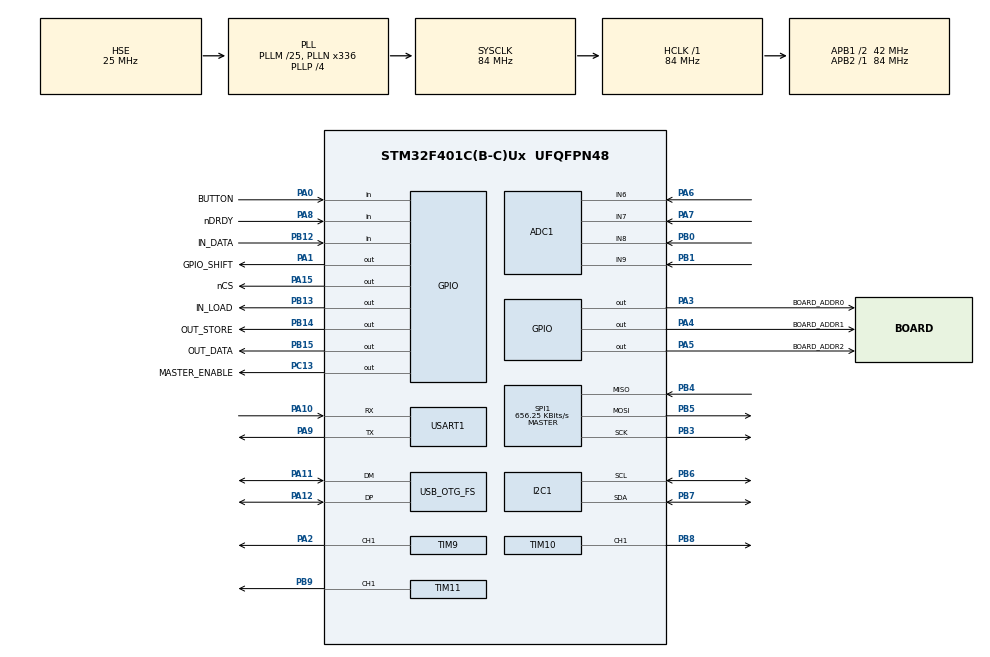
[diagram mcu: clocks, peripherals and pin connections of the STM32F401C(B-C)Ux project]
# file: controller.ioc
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ADC1.Channel-0\#ChannelRegularConversion=ADC_CHANNEL_VREFINT
ADC1.Channel-1\#ChannelRegularConversion=ADC_CHANNEL_6
ADC1.Channel-2\#ChannelRegularConversion=ADC_CHANNEL_7
ADC1.Channel-3\#ChannelRegularConversion=ADC_CHANNEL_VREFINT
ADC1.Channel-4\#ChannelRegularConversion=ADC_CHANNEL_8
ADC1.Channel-5\#ChannelRegularConversion=ADC_CHANNEL_9
ADC1.Channel-6\#ChannelRegularConversion=ADC_CHANNEL_TEMPSENSOR
ADC1.Channel-8\#ChannelRegularConversion=ADC_CHANNEL_VREFINT
ADC1.ClockPrescaler=ADC_CLOCK_SYNC_PCLK_DIV8
ADC1.ContinuousConvMode=DISABLE
ADC1.DMAContinuousRequests=ENABLE
ADC1.EOCSelection=ADC_EOC_SEQ_CONV
ADC1.ExternalTrigConv=ADC_EXTERNALTRIGCONV_T3_TRGO
ADC1.InjNumberOfConversion=0
ADC1.NbrOfConversion=8
ADC1.NbrOfConversionFlag=1
ADC1.Rank-0\#ChannelRegularConversion=1
ADC1.Rank-1\#ChannelRegularConversion=2
ADC1.Rank-2\#ChannelRegularConversion=3
ADC1.Rank-3\#ChannelRegularConversion=4
ADC1.Rank-4\#ChannelRegularConversion=5
ADC1.Rank-5\#ChannelRegularConversion=6
ADC1.Rank-6\#ChannelRegularConversion=7
ADC1.Rank-8\#ChannelRegularConversion=8
ADC1.SamplingTime-0\#ChannelRegularConversion=ADC_SAMPLETIME_480CYCLES
ADC1.SamplingTime-1\#ChannelRegularConversion=ADC_SAMPLETIME_480CYCLES
ADC1.SamplingTime-2\#ChannelRegularConversion=ADC_SAMPLETIME_480CYCLES
ADC1.SamplingTime-3\#ChannelRegularConversion=ADC_SAMPLETIME_480CYCLES
ADC1.SamplingTime-4\#ChannelRegularConversion=ADC_SAMPLETIME_480CYCLES
ADC1.SamplingTime-5\#ChannelRegularConversion=ADC_SAMPLETIME_480CYCLES
ADC1.SamplingTime-6\#ChannelRegularConversion=ADC_SAMPLETIME_480CYCLES
ADC1.SamplingTime-8\#ChannelRegularConversion=ADC_SAMPLETIME_480CYCLES
ADC1.ScanConvMode=ENABLE
ADC1.master=1
Dma.ADC1.0.Direction=DMA_PERIPH_TO_MEMORY
Dma.ADC1.0.FIFOMode=DMA_FIFOMODE_ENABLE
Dma.ADC1.0.FIFOThreshold=DMA_FIFO_THRESHOLD_FULL
Dma.ADC1.0.Instance=DMA2_Stream4
Dma.ADC1.0.MemBurst=DMA_MBURST_INC8
Dma.ADC1.0.MemDataAlignment=DMA_MDATAALIGN_HALFWORD
Dma.ADC1.0.MemInc=DMA_MINC_ENABLE
Dma.ADC1.0.Mode=DMA_CIRCULAR
Dma.ADC1.0.PeriphBurst=DMA_PBURST_SINGLE
Dma.ADC1.0.PeriphDataAlignment=DMA_PDATAALIGN_HALFWORD
Dma.ADC1.0.PeriphInc=DMA_PINC_DISABLE
Dma.ADC1.0.Priority=DMA_PRIORITY_MEDIUM
Dma.Request0=ADC1
I2C1.I2C_Mode=I2C_Fast
Mcu.Family=STM32F4
Mcu.Name=STM32F401C(B-C)Ux
Mcu.Package=UFQFPN48
Mcu.UserConstants=MOTOR_TIMER_MIN_VALUE,200-1;MOTOR_TIMER_PULSE_WIDTH,MOTOR_TIMER_MIN_VALUE/2
NVIC.DMA2_Stream4_IRQn=true\:2\:0\:true\:false\:true\:false\:true\:true
NVIC.OTG_FS_IRQn=true\:0\:0\:false\:false\:true\:false\:true\:true
NVIC.PriorityGroup=NVIC_PRIORITYGROUP_4
NVIC.RTC_Alarm_IRQn=true\:4\:0\:true\:false\:true\:true\:true\:true
NVIC.TIM1_UP_TIM10_IRQn=true\:2\:0\:true\:false\:true\:true\:true\:true
NVIC.TIM3_IRQn=true\:3\:0\:true\:false\:true\:true\:true\:true
NVIC.TIM4_IRQn=true\:0\:0\:false\:false\:true\:true\:true\:true
NVIC.USART1_IRQn=true\:0\:0\:false\:false\:true\:true\:true\:true
PA0-WKUP.GPIO_Label=BUTTON
PA0-WKUP.GPIO_PuPd=GPIO_PULLUP
PA0-WKUP.Signal=GPIO_Input
PA1.GPIO_Label=GPIO_SHIFT
PA1.Signal=GPIO_Output
PA10.GPIO_Speed=GPIO_SPEED_FREQ_MEDIUM
PA10.Mode=Asynchronous
PA10.Signal=USART1_RX
PA11.GPIO_Speed=GPIO_SPEED_FREQ_HIGH
PA11.Mode=Device_Only
PA11.Signal=USB_OTG_FS_DM
PA12.GPIO_Speed=GPIO_SPEED_FREQ_HIGH
PA12.Mode=Device_Only
PA12.Signal=USB_OTG_FS_DP
PA13.Mode=Serial_Wire
PA13.Signal=SYS_JTMS-SWDIO
PA14.Mode=Serial_Wire
PA14.Signal=SYS_JTCK-SWCLK
PA15.GPIO_Label=nCS
PA15.Signal=GPIO_Output
PA2.Signal=S_TIM9_CH1
PA3.GPIO_Label=BOARD_ADDR0
PA3.Signal=GPIO_Output
PA4.GPIO_Label=BOARD_ADDR1
PA4.Signal=GPIO_Output
PA5.GPIO_Label=BOARD_ADDR2
PA5.Signal=GPIO_Output
PA6.Signal=ADCx_IN6
PA7.Signal=ADCx_IN7
PA8.GPIO_Label=nDRDY
PA8.GPIO_PuPd=GPIO_PULLUP
PA8.Signal=GPIO_Input
PA9.GPIO_Speed=GPIO_SPEED_FREQ_MEDIUM
PA9.Mode=Asynchronous
PA9.Signal=USART1_TX
PB0.Signal=ADCx_IN8
PB1.Signal=ADCx_IN9
PB12.GPIO_Label=IN_DATA
PB12.Signal=GPIO_Input
PB13.GPIO_Label=IN_LOAD
PB13.Signal=GPIO_Output
PB14.GPIO_Label=OUT_STORE
PB14.Signal=GPIO_Output
PB15.GPIO_Label=OUT_DATA
PB15.Signal=GPIO_Output
PB3.GPIO_Speed=GPIO_SPEED_FREQ_MEDIUM
PB3.Mode=Full_Duplex_Master
PB3.Signal=SPI1_SCK
PB4.GPIO_Speed=GPIO_SPEED_FREQ_MEDIUM
PB4.Mode=Full_Duplex_Master
PB4.Signal=SPI1_MISO
PB5.GPIO_Speed=GPIO_SPEED_FREQ_MEDIUM
PB5.Mode=Full_Duplex_Master
PB5.Signal=SPI1_MOSI
PB6.GPIO_Pu=GPIO_PULLUP
PB6.GPIO_Speed=GPIO_SPEED_FREQ_MEDIUM
PB6.Mode=I2C
PB6.Signal=I2C1_SCL
PB7.GPIO_Pu=GPIO_PULLUP
PB7.GPIO_Speed=GPIO_SPEED_FREQ_MEDIUM
PB7.Mode=I2C
PB7.Signal=I2C1_SDA
PB8.Signal=S_TIM10_CH1
PB9.Signal=S_TIM11_CH1
PC13-ANTI_TAMP.GPIO_Label=MASTER_ENABLE
PC13-ANTI_TAMP.Signal=GPIO_Output
PC14-OSC32_IN.Mode=LSE-External-Oscillator
PC14-OSC32_IN.Signal=RCC_OSC32_IN
PC15-OSC32_OUT.Mode=LSE-External-Oscillator
PC15-OSC32_OUT.Signal=RCC_OSC32_OUT
PH0\ -\ OSC_IN.Mode=HSE-External-Oscillator
PH0\ -\ OSC_IN.Signal=RCC_OSC_IN
PH1\ -\ OSC_OUT.Mode=HSE-External-Oscillator
PH1\ -\ OSC_OUT.Signal=RCC_OSC_OUT
ProjectManager.HeapSize=0x200
ProjectManager.StackSize=0x400
ProjectManager.TargetToolchain=Makefile
RCC.48MHZClocksFreq_Value=48000000
RCC.AHBFreq_Value=84000000
RCC.APB1CLKDivider=RCC_HCLK_DIV2
RCC.APB1Freq_Value=42000000
RCC.APB1TimFreq_Value=84000000
RCC.APB2Freq_Value=84000000
RCC.APB2TimFreq_Value=84000000
RCC.CortexFreq_Value=84000000
RCC.EnbaleCSS=true
RCC.HCLKFreq_Value=84000000
RCC.HSE_VALUE=25000000
RCC.HSICalibrationValue=16
RCC.HSI_VALUE=16000000
RCC.LSE_Timout=500
RCC.PLLM=25
RCC.PLLN=336
RCC.PLLP=RCC_PLLP_DIV4
RCC.PLLQ=7
RCC.PWR_Regulator_Voltage_Scale=PWR_REGULATOR_VOLTAGE_SCALE2
RCC.RCC_RTC_Clock_SourceVirtual=RCC_RTCCLKSOURCE_LSE
RCC.SYSCLKFreq_VALUE=84000000
RCC.SYSCLKSource=RCC_SYSCLKSOURCE_PLLCLK
RCC.VCOOutputFreq_Value=336000000
RTC.Alarm=RTC_ALARM_A
RTC.AlarmMaskDateWeekDay=RTC_ALARMMASK_DATEWEEKDAY
RTC.AlarmMaskHours=RTC_ALARMMASK_HOURS
RTC.AlarmMaskMinutes=RTC_ALARMMASK_MINUTES
RTC.AlarmMaskSeconds=RTC_ALARMMASK_SECONDS
RTC.AlarmSubSecondMask=RTC_ALARMSUBSECONDMASK_ALL
RTC.AsynchPrediv=127
RTC.Format=RTC_FORMAT_BCD
RTC.SubSeconds_A=0
RTC.SynchPrediv=255
RTC.Year=21
SH.ADCx_IN6.0=ADC1_IN6,IN6
SH.ADCx_IN7.0=ADC1_IN7,IN7
SH.ADCx_IN8.0=ADC1_IN8,IN8
SH.ADCx_IN9.0=ADC1_IN9,IN9
SH.S_TIM10_CH1.0=TIM10_CH1,PWM Generation1 CH1
SH.S_TIM11_CH1.0=TIM11_CH1,PWM Generation1 CH1
SH.S_TIM9_CH1.0=TIM9_CH1,PWM Generation1 CH1
SPI1.BaudRatePrescaler=SPI_BAUDRATEPRESCALER_128
SPI1.CLKPhase=SPI_PHASE_2EDGE
SPI1.CRCCalculation=SPI_CRCCALCULATION_DISABLE
SPI1.CalculateBaudRate=656.25 KBits/s
SPI1.Direction=SPI_DIRECTION_2LINES
SPI1.Mode=SPI_MODE_MASTER
SPI1.VirtualType=VM_MASTER
TIM10.AutoReloadPreload=TIM_AUTORELOAD_PRELOAD_ENABLE
TIM10.Channel=TIM_CHANNEL_1
TIM10.Prescaler=130-1
TIM10.Pulse=MOTOR_TIMER_PULSE_WIDTH
TIM11.AutoReloadPreload=TIM_AUTORELOAD_PRELOAD_ENABLE
TIM11.Channel=TIM_CHANNEL_1
TIM11.Prescaler=130-1
TIM11.Pulse=MOTOR_TIMER_PULSE_WIDTH
TIM3.Period=60000-1
TIM3.Prescaler=140-1
TIM3.TIM_MasterOutputTrigger=TIM_TRGO_UPDATE
TIM3.TIM_MasterSlaveMode=TIM_MASTERSLAVEMODE_ENABLE
TIM4.Period=30000
TIM4.Prescaler=140-1
TIM4.TIM_MasterOutputTrigger=TIM_TRGO_UPDATE
TIM4.TIM_MasterSlaveMode=TIM_MASTERSLAVEMODE_ENABLE
TIM5.Period=4294967295
TIM5.Prescaler=84-1
TIM9.AutoReloadPreload=TIM_AUTORELOAD_PRELOAD_ENABLE
TIM9.Channel-PWM\ Generation1\ CH1=TIM_CHANNEL_1
TIM9.Prescaler=130-1
TIM9.Pulse-PWM\ Generation1\ CH1=MOTOR_TIMER_PULSE_WIDTH
USART1.Parity=PARITY_ODD
USART1.VirtualMode=VM_ASYNC
USB_DEVICE.APP_RX_DATA_SIZE=512
USB_DEVICE.APP_TX_DATA_SIZE=512
USB_DEVICE.CLASS_NAME_FS=CDC
USB_DEVICE.MANUFACTURER_STRING=Kutukov Pavel
USB_DEVICE.PID_CDC_FS=0x5740
USB_DEVICE.PRODUCT_STRING_CDC_FS=pO2 regulator - STM32 Serial
USB_DEVICE.USBD_MAX_STR_DESC_SIZ=128
USB_DEVICE.USBD_SELF_POWERED=0
USB_DEVICE.VID=0x483
USB_DEVICE.VirtualMode=Cdc
USB_DEVICE.VirtualModeFS=Cdc_FS
USB_OTG_FS.VirtualMode=Device_Only
VP_ADC1_TempSens_Input.Mode=IN-TempSens
VP_ADC1_Vref_Input.Mode=IN-Vrefint
VP_RTC_VS_RTC_Activate.Mode=RTC_Enabled
VP_RTC_VS_RTC_Alarm_A_Intern.Mode=Alarm A
VP_RTC_VS_RTC_Calendar.Mode=RTC_Calendar
VP_TIM10_VS_ClockSourceINT.Mode=Enable_Timer
VP_TIM11_VS_ClockSourceINT.Mode=Enable_Timer
VP_TIM3_VS_ClockSourceINT.Mode=Internal
VP_TIM4_VS_ClockSourceINT.Mode=Internal
VP_TIM4_VS_ClockSourceITR.Mode=TriggerSource_ITR2
VP_TIM4_VS_ControllerModeTrigger.Mode=Trigger Mode
VP_TIM4_VS_OPM.Mode=OPM_bit
VP_TIM5_VS_ClockSourceINT.Mode=Internal
VP_TIM9_VS_ClockSourceINT.Mode=Internal
VP_USB_DEVICE_VS_USB_DEVICE_CDC_FS.Mode=CDC_FS
board=custom

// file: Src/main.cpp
/* USER CODE BEGIN Header */
/**
  ******************************************************************************
  * @file           : main.c
  * @brief          : Main program body
  ******************************************************************************
  * @attention
  *
  * Copyright (c) 2023 STMicroelectronics.
  * All rights reserved.
  *
  * This software is licensed under terms that can be found in the LICENSE file
  * in the root directory of this software component.
  * If no LICENSE file comes with this software, it is provided AS-IS.
  *
  ******************************************************************************
  */
/* USER CODE END Header */
#include "main.h"
#include "usb_device.h"

/* USER CODE BEGIN Includes */
#include "user.h"
/* USER CODE END Includes */

ADC_HandleTypeDef hadc1;
DMA_HandleTypeDef hdma_adc1;

I2C_HandleTypeDef hi2c1;

RTC_HandleTypeDef hrtc;

SPI_HandleTypeDef hspi1;

TIM_HandleTypeDef htim3;
TIM_HandleTypeDef htim4;
TIM_HandleTypeDef htim5;
TIM_HandleTypeDef htim9;
TIM_HandleTypeDef htim10;
TIM_HandleTypeDef htim11;

UART_HandleTypeDef huart1;

void SystemClock_Config(void);
static void MX_GPIO_Init(void);
static void MX_DMA_Init(void);
static void MX_ADC1_Init(void);
static void MX_I2C1_Init(void);
static void MX_SPI1_Init(void);
static void MX_TIM3_Init(void);
static void MX_TIM9_Init(void);
static void MX_TIM10_Init(void);
static void MX_TIM11_Init(void);
static void MX_RTC_Init(void);
static void MX_USART1_UART_Init(void);
static void MX_TIM5_Init(void);
static void MX_TIM4_Init(void);

int main(void)
{

  /* MCU Configuration--------------------------------------------------------*/

  /* Reset of all peripherals, Initializes the Flash interface and the Systick. */
  HAL_Init();

  /* Configure the system clock */
  SystemClock_Config();

  /* Initialize all configured peripherals */
  MX_GPIO_Init();
  MX_DMA_Init();
  MX_ADC1_Init();
  MX_I2C1_Init();
  MX_SPI1_Init();
  MX_TIM3_Init();
  MX_TIM9_Init();
  MX_TIM10_Init();
  MX_TIM11_Init();
  MX_RTC_Init();
  MX_USART1_UART_Init();
  MX_USB_DEVICE_Init();
  MX_TIM5_Init();
  MX_TIM4_Init();
  /* USER CODE BEGIN 2 */
  user::setup(&hspi1, &hspi1, &hi2c1, &hadc1, &huart1);
  /* USER CODE END 2 */

  /* Infinite loop */
  while (1)
  {
    user::main();
  }
}

void SystemClock_Config(void)
{
  RCC_OscInitTypeDef RCC_OscInitStruct = {0};
  RCC_ClkInitTypeDef RCC_ClkInitStruct = {0};

  /** Configure the main internal regulator output voltage
  */
  __HAL_RCC_PWR_CLK_ENABLE();
  __HAL_PWR_VOLTAGESCALING_CONFIG(PWR_REGULATOR_VOLTAGE_SCALE2);

  /** Initializes the RCC Oscillators according to the specified parameters
  * in the RCC_OscInitTypeDef structure.
  */
  RCC_OscInitStruct.OscillatorType = RCC_OSCILLATORTYPE_HSE|RCC_OSCILLATORTYPE_LSE;
  RCC_OscInitStruct.HSEState = RCC_HSE_ON;
  RCC_OscInitStruct.LSEState = RCC_LSE_ON;
  RCC_OscInitStruct.PLL.PLLState = RCC_PLL_ON;
  RCC_OscInitStruct.PLL.PLLSource = RCC_PLLSOURCE_HSE;
  RCC_OscInitStruct.PLL.PLLM = 25;
  RCC_OscInitStruct.PLL.PLLN = 336;
  RCC_OscInitStruct.PLL.PLLP = RCC_PLLP_DIV4;
  RCC_OscInitStruct.PLL.PLLQ = 7;
  if (HAL_RCC_OscConfig(&RCC_OscInitStruct) != HAL_OK)
  {
    Error_Handler();
  }

  /** Initializes the CPU, AHB and APB buses clocks
  */
  RCC_ClkInitStruct.ClockType = RCC_CLOCKTYPE_HCLK|RCC_CLOCKTYPE_SYSCLK
                              |RCC_CLOCKTYPE_PCLK1|RCC_CLOCKTYPE_PCLK2;
  RCC_ClkInitStruct.SYSCLKSource = RCC_SYSCLKSOURCE_PLLCLK;
  RCC_ClkInitStruct.AHBCLKDivider = RCC_SYSCLK_DIV1;
  RCC_ClkInitStruct.APB1CLKDivider = RCC_HCLK_DIV2;
  RCC_ClkInitStruct.APB2CLKDivider = RCC_HCLK_DIV1;

  if (HAL_RCC_ClockConfig(&RCC_ClkInitStruct, FLASH_LATENCY_2) != HAL_OK)
  {
    Error_Handler();
  }

  /** Enables the Clock Security System
  */
  HAL_RCC_EnableCSS();
}

static void MX_ADC1_Init(void)
{

  ADC_ChannelConfTypeDef sConfig = {0};

  /** Configure the global features of the ADC (Clock, Resolution, Data Alignment and number of conversion)
  */
  hadc1.Instance = ADC1;
  hadc1.Init.ClockPrescaler = ADC_CLOCK_SYNC_PCLK_DIV8;
  hadc1.Init.Resolution = ADC_RESOLUTION_12B;
  hadc1.Init.ScanConvMode = ENABLE;
  hadc1.Init.ContinuousConvMode = DISABLE;
  hadc1.Init.DiscontinuousConvMode = DISABLE;
  hadc1.Init.ExternalTrigConvEdge = ADC_EXTERNALTRIGCONVEDGE_RISING;
  hadc1.Init.ExternalTrigConv = ADC_EXTERNALTRIGCONV_T3_TRGO;
  hadc1.Init.DataAlign = ADC_DATAALIGN_RIGHT;
  hadc1.Init.NbrOfConversion = 8;
  hadc1.Init.DMAContinuousRequests = ENABLE;
  hadc1.Init.EOCSelection = ADC_EOC_SEQ_CONV;
  if (HAL_ADC_Init(&hadc1) != HAL_OK)
  {
    Error_Handler();
  }

  /** Configure for the selected ADC regular channel its corresponding rank in the sequencer and its sample time.
  */
  sConfig.Channel = ADC_CHANNEL_VREFINT;
  sConfig.Rank = 1;
  sConfig.SamplingTime = ADC_SAMPLETIME_480CYCLES;
  if (HAL_ADC_ConfigChannel(&hadc1, &sConfig) != HAL_OK)
  {
    Error_Handler();
  }

  /** Configure for the selected ADC regular channel its corresponding rank in the sequencer and its sample time.
  */
  sConfig.Channel = ADC_CHANNEL_6;
  sConfig.Rank = 2;
  if (HAL_ADC_ConfigChannel(&hadc1, &sConfig) != HAL_OK)
  {
    Error_Handler();
  }

  /** Configure for the selected ADC regular channel its corresponding rank in the sequencer and its sample time.
  */
  sConfig.Channel = ADC_CHANNEL_7;
  sConfig.Rank = 3;
  if (HAL_ADC_ConfigChannel(&hadc1, &sConfig) != HAL_OK)
  {
    Error_Handler();
  }

  /** Configure for the selected ADC regular channel its corresponding rank in the sequencer and its sample time.
  */
  sConfig.Channel = ADC_CHANNEL_VREFINT;
  sConfig.Rank = 4;
  if (HAL_ADC_ConfigChannel(&hadc1, &sConfig) != HAL_OK)
  {
    Error_Handler();
  }

  /** Configure for the selected ADC regular channel its corresponding rank in the sequencer and its sample time.
  */
  sConfig.Channel = ADC_CHANNEL_8;
  sConfig.Rank = 5;
  if (HAL_ADC_ConfigChannel(&hadc1, &sConfig) != HAL_OK)
  {
    Error_Handler();
  }

  /** Configure for the selected ADC regular channel its corresponding rank in the sequencer and its sample time.
  */
  sConfig.Channel = ADC_CHANNEL_9;
  sConfig.Rank = 6;
  if (HAL_ADC_ConfigChannel(&hadc1, &sConfig) != HAL_OK)
  {
    Error_Handler();
  }

  /** Configure for the selected ADC regular channel its corresponding rank in the sequencer and its sample time.
  */
  sConfig.Channel = ADC_CHANNEL_TEMPSENSOR;
  sConfig.Rank = 7;
  if (HAL_ADC_ConfigChannel(&hadc1, &sConfig) != HAL_OK)
  {
    Error_Handler();
  }

  /** Configure for the selected ADC regular channel its corresponding rank in the sequencer and its sample time.
  */
  sConfig.Channel = ADC_CHANNEL_VREFINT;
  sConfig.Rank = 8;
  if (HAL_ADC_ConfigChannel(&hadc1, &sConfig) != HAL_OK)
  {
    Error_Handler();
  }

}

static void MX_I2C1_Init(void)
{

  hi2c1.Instance = I2C1;
  hi2c1.Init.ClockSpeed = 400000;
  hi2c1.Init.DutyCycle = I2C_DUTYCYCLE_2;
  hi2c1.Init.OwnAddress1 = 0;
  hi2c1.Init.AddressingMode = I2C_ADDRESSINGMODE_7BIT;
  hi2c1.Init.DualAddressMode = I2C_DUALADDRESS_DISABLE;
  hi2c1.Init.OwnAddress2 = 0;
  hi2c1.Init.GeneralCallMode = I2C_GENERALCALL_DISABLE;
  hi2c1.Init.NoStretchMode = I2C_NOSTRETCH_DISABLE;
  if (HAL_I2C_Init(&hi2c1) != HAL_OK)
  {
    Error_Handler();
  }

}

static void MX_RTC_Init(void)
{

  RTC_TimeTypeDef sTime = {0};
  RTC_DateTypeDef sDate = {0};
  RTC_AlarmTypeDef sAlarm = {0};

  /** Initialize RTC Only
  */
  hrtc.Instance = RTC;
  hrtc.Init.HourFormat = RTC_HOURFORMAT_24;
  hrtc.Init.AsynchPrediv = 127;
  hrtc.Init.SynchPrediv = 255;
  hrtc.Init.OutPut = RTC_OUTPUT_DISABLE;
  hrtc.Init.OutPutPolarity = RTC_OUTPUT_POLARITY_HIGH;
  hrtc.Init.OutPutType = RTC_OUTPUT_TYPE_OPENDRAIN;
  if (HAL_RTC_Init(&hrtc) != HAL_OK)
  {
    Error_Handler();
  }

  /** Initialize RTC and set the Time and Date
  */
  sTime.Hours = 0x0;
  sTime.Minutes = 0x0;
  sTime.Seconds = 0x0;
  sTime.DayLightSaving = RTC_DAYLIGHTSAVING_NONE;
  sTime.StoreOperation = RTC_STOREOPERATION_RESET;
  if (HAL_RTC_SetTime(&hrtc, &sTime, RTC_FORMAT_BCD) != HAL_OK)
  {
    Error_Handler();
  }
  sDate.WeekDay = RTC_WEEKDAY_MONDAY;
  sDate.Month = RTC_MONTH_JANUARY;
  sDate.Date = 0x1;
  sDate.Year = 0x21;

  if (HAL_RTC_SetDate(&hrtc, &sDate, RTC_FORMAT_BCD) != HAL_OK)
  {
    Error_Handler();
  }

  /** Enable the Alarm A
  */
  sAlarm.AlarmTime.Hours = 0x0;
  sAlarm.AlarmTime.Minutes = 0x0;
  sAlarm.AlarmTime.Seconds = 0x0;
  sAlarm.AlarmTime.SubSeconds = 0x0;
  sAlarm.AlarmTime.DayLightSaving = RTC_DAYLIGHTSAVING_NONE;
  sAlarm.AlarmTime.StoreOperation = RTC_STOREOPERATION_RESET;
  sAlarm.AlarmMask = RTC_ALARMMASK_ALL;
  sAlarm.AlarmSubSecondMask = RTC_ALARMSUBSECONDMASK_ALL;
  sAlarm.AlarmDateWeekDaySel = RTC_ALARMDATEWEEKDAYSEL_DATE;
  sAlarm.AlarmDateWeekDay = 0x1;
  sAlarm.Alarm = RTC_ALARM_A;
  if (HAL_RTC_SetAlarm_IT(&hrtc, &sAlarm, RTC_FORMAT_BCD) != HAL_OK)
  {
    Error_Handler();
  }

}

static void MX_SPI1_Init(void)
{

  /* SPI1 parameter configuration*/
  hspi1.Instance = SPI1;
  hspi1.Init.Mode = SPI_MODE_MASTER;
  hspi1.Init.Direction = SPI_DIRECTION_2LINES;
  hspi1.Init.DataSize = SPI_DATASIZE_8BIT;
  hspi1.Init.CLKPolarity = SPI_POLARITY_LOW;
  hspi1.Init.CLKPhase = SPI_PHASE_2EDGE;
  hspi1.Init.NSS = SPI_NSS_SOFT;
  hspi1.Init.BaudRatePrescaler = SPI_BAUDRATEPRESCALER_128;
  hspi1.Init.FirstBit = SPI_FIRSTBIT_MSB;
  hspi1.Init.TIMode = SPI_TIMODE_DISABLE;
  hspi1.Init.CRCCalculation = SPI_CRCCALCULATION_DISABLE;
  hspi1.Init.CRCPolynomial = 10;
  if (HAL_SPI_Init(&hspi1) != HAL_OK)
  {
    Error_Handler();
  }

}

static void MX_TIM3_Init(void)
{

  TIM_ClockConfigTypeDef sClockSourceConfig = {0};
  TIM_MasterConfigTypeDef sMasterConfig = {0};

  htim3.Instance = TIM3;
  htim3.Init.Prescaler = 140-1;
  htim3.Init.CounterMode = TIM_COUNTERMODE_UP;
  htim3.Init.Period = 60000-1;
  htim3.Init.ClockDivision = TIM_CLOCKDIVISION_DIV1;
  htim3.Init.AutoReloadPreload = TIM_AUTORELOAD_PRELOAD_DISABLE;
  if (HAL_TIM_Base_Init(&htim3) != HAL_OK)
  {
    Error_Handler();
  }
  sClockSourceConfig.ClockSource = TIM_CLOCKSOURCE_INTERNAL;
  if (HAL_TIM_ConfigClockSource(&htim3, &sClockSourceConfig) != HAL_OK)
  {
    Error_Handler();
  }
  sMasterConfig.MasterOutputTrigger = TIM_TRGO_UPDATE;
  sMasterConfig.MasterSlaveMode = TIM_MASTERSLAVEMODE_ENABLE;
  if (HAL_TIMEx_MasterConfigSynchronization(&htim3, &sMasterConfig) != HAL_OK)
  {
    Error_Handler();
  }
  /* USER CODE BEGIN TIM3_Init 2 */
  HAL_TIM_Base_Start_IT(&htim3);
  /* USER CODE END TIM3_Init 2 */

}

static void MX_TIM4_Init(void)
{

  TIM_ClockConfigTypeDef sClockSourceConfig = {0};
  TIM_SlaveConfigTypeDef sSlaveConfig = {0};
  TIM_MasterConfigTypeDef sMasterConfig = {0};

  htim4.Instance = TIM4;
  htim4.Init.Prescaler = 140-1;
  htim4.Init.CounterMode = TIM_COUNTERMODE_UP;
  htim4.Init.Period = 10000;
  htim4.Init.ClockDivision = TIM_CLOCKDIVISION_DIV1;
  htim4.Init.AutoReloadPreload = TIM_AUTORELOAD_PRELOAD_DISABLE;
  if (HAL_TIM_Base_Init(&htim4) != HAL_OK)
  {
    Error_Handler();
  }
  sClockSourceConfig.ClockSource = TIM_CLOCKSOURCE_INTERNAL;
  if (HAL_TIM_ConfigClockSource(&htim4, &sClockSourceConfig) != HAL_OK)
  {
    Error_Handler();
  }
  if (HAL_TIM_OnePulse_Init(&htim4, TIM_OPMODE_SINGLE) != HAL_OK)
  {
    Error_Handler();
  }
  sSlaveConfig.SlaveMode = TIM_SLAVEMODE_TRIGGER;
  sSlaveConfig.InputTrigger = TIM_TS_ITR2;
  if (HAL_TIM_SlaveConfigSynchro(&htim4, &sSlaveConfig) != HAL_OK)
  {
    Error_Handler();
  }
  sMasterConfig.MasterOutputTrigger = TIM_TRGO_UPDATE;
  sMasterConfig.MasterSlaveMode = TIM_MASTERSLAVEMODE_ENABLE;
  if (HAL_TIMEx_MasterConfigSynchronization(&htim4, &sMasterConfig) != HAL_OK)
  {
    Error_Handler();
  }
  /* USER CODE BEGIN TIM4_Init 2 */
  HAL_TIM_Base_Start_IT(&htim4);
  /* USER CODE END TIM4_Init 2 */

}

static void MX_TIM5_Init(void)
{

  TIM_ClockConfigTypeDef sClockSourceConfig = {0};
  TIM_MasterConfigTypeDef sMasterConfig = {0};

  htim5.Instance = TIM5;
  htim5.Init.Prescaler = 84-1;
  htim5.Init.CounterMode = TIM_COUNTERMODE_UP;
  htim5.Init.Period = 4294967295;
  htim5.Init.ClockDivision = TIM_CLOCKDIVISION_DIV1;
  htim5.Init.AutoReloadPreload = TIM_AUTORELOAD_PRELOAD_DISABLE;
  if (HAL_TIM_Base_Init(&htim5) != HAL_OK)
  {
    Error_Handler();
  }
  sClockSourceConfig.ClockSource = TIM_CLOCKSOURCE_INTERNAL;
  if (HAL_TIM_ConfigClockSource(&htim5, &sClockSourceConfig) != HAL_OK)
  {
    Error_Handler();
  }
  sMasterConfig.MasterOutputTrigger = TIM_TRGO_RESET;
  sMasterConfig.MasterSlaveMode = TIM_MASTERSLAVEMODE_DISABLE;
  if (HAL_TIMEx_MasterConfigSynchronization(&htim5, &sMasterConfig) != HAL_OK)
  {
    Error_Handler();
  }
  /* USER CODE BEGIN TIM5_Init 2 */
  HAL_TIM_Base_Start(&htim5);
  /* USER CODE END TIM5_Init 2 */

}

static void MX_TIM9_Init(void)
{

  TIM_ClockConfigTypeDef sClockSourceConfig = {0};
  TIM_OC_InitTypeDef sConfigOC = {0};

  htim9.Instance = TIM9;
  htim9.Init.Prescaler = 130-1;
  htim9.Init.CounterMode = TIM_COUNTERMODE_UP;
  htim9.Init.Period = 65535;
  htim9.Init.ClockDivision = TIM_CLOCKDIVISION_DIV1;
  htim9.Init.AutoReloadPreload = TIM_AUTORELOAD_PRELOAD_ENABLE;
  if (HAL_TIM_Base_Init(&htim9) != HAL_OK)
  {
    Error_Handler();
  }
  sClockSourceConfig.ClockSource = TIM_CLOCKSOURCE_INTERNAL;
  if (HAL_TIM_ConfigClockSource(&htim9, &sClockSourceConfig) != HAL_OK)
  {
    Error_Handler();
  }
  if (HAL_TIM_PWM_Init(&htim9) != HAL_OK)
  {
    Error_Handler();
  }
  sConfigOC.OCMode = TIM_OCMODE_PWM1;
  sConfigOC.Pulse = MOTOR_TIMER_PULSE_WIDTH;
  sConfigOC.OCPolarity = TIM_OCPOLARITY_HIGH;
  sConfigOC.OCFastMode = TIM_OCFAST_DISABLE;
  if (HAL_TIM_PWM_ConfigChannel(&htim9, &sConfigOC, TIM_CHANNEL_1) != HAL_OK)
  {
    Error_Handler();
  }
  /* USER CODE BEGIN TIM9_Init 2 */
  HAL_TIM_Base_Start(&htim9);
  HAL_TIM_PWM_Start(&htim9, TIM_CHANNEL_1);
  /* USER CODE END TIM9_Init 2 */
  HAL_TIM_MspPostInit(&htim9);

}

static void MX_TIM10_Init(void)
{

  TIM_OC_InitTypeDef sConfigOC = {0};

  htim10.Instance = TIM10;
  htim10.Init.Prescaler = 130-1;
  htim10.Init.CounterMode = TIM_COUNTERMODE_UP;
  htim10.Init.Period = 65535;
  htim10.Init.ClockDivision = TIM_CLOCKDIVISION_DIV1;
  htim10.Init.AutoReloadPreload = TIM_AUTORELOAD_PRELOAD_ENABLE;
  if (HAL_TIM_Base_Init(&htim10) != HAL_OK)
  {
    Error_Handler();
  }
  if (HAL_TIM_PWM_Init(&htim10) != HAL_OK)
  {
    Error_Handler();
  }
  sConfigOC.OCMode = TIM_OCMODE_PWM1;
  sConfigOC.Pulse = MOTOR_TIMER_PULSE_WIDTH;
  sConfigOC.OCPolarity = TIM_OCPOLARITY_HIGH;
  sConfigOC.OCFastMode = TIM_OCFAST_DISABLE;
  if (HAL_TIM_PWM_ConfigChannel(&htim10, &sConfigOC, TIM_CHANNEL_1) != HAL_OK)
  {
    Error_Handler();
  }
  /* USER CODE BEGIN TIM10_Init 2 */
  HAL_TIM_Base_Start(&htim10);
  HAL_TIM_PWM_Start(&htim10, TIM_CHANNEL_1);
  /* USER CODE END TIM10_Init 2 */
  HAL_TIM_MspPostInit(&htim10);

}

static void MX_TIM11_Init(void)
{

  TIM_OC_InitTypeDef sConfigOC = {0};

  htim11.Instance = TIM11;
  htim11.Init.Prescaler = 130-1;
  htim11.Init.CounterMode = TIM_COUNTERMODE_UP;
  htim11.Init.Period = 65535;
  htim11.Init.ClockDivision = TIM_CLOCKDIVISION_DIV1;
  htim11.Init.AutoReloadPreload = TIM_AUTORELOAD_PRELOAD_ENABLE;
  if (HAL_TIM_Base_Init(&htim11) != HAL_OK)
  {
    Error_Handler();
  }
  if (HAL_TIM_PWM_Init(&htim11) != HAL_OK)
  {
    Error_Handler();
  }
  sConfigOC.OCMode = TIM_OCMODE_PWM1;
  sConfigOC.Pulse = MOTOR_TIMER_PULSE_WIDTH;
  sConfigOC.OCPolarity = TIM_OCPOLARITY_HIGH;
  sConfigOC.OCFastMode = TIM_OCFAST_DISABLE;
  if (HAL_TIM_PWM_ConfigChannel(&htim11, &sConfigOC, TIM_CHANNEL_1) != HAL_OK)
  {
    Error_Handler();
  }
  /* USER CODE BEGIN TIM11_Init 2 */
  HAL_TIM_Base_Start(&htim11);
  HAL_TIM_PWM_Start(&htim11, TIM_CHANNEL_1);
  /* USER CODE END TIM11_Init 2 */
  HAL_TIM_MspPostInit(&htim11);

}

static void MX_USART1_UART_Init(void)
{

  huart1.Instance = USART1;
  huart1.Init.BaudRate = 115200;
  huart1.Init.WordLength = UART_WORDLENGTH_8B;
  huart1.Init.StopBits = UART_STOPBITS_1;
  huart1.Init.Parity = UART_PARITY_ODD;
  huart1.Init.Mode = UART_MODE_TX_RX;
  huart1.Init.HwFlowCtl = UART_HWCONTROL_NONE;
  huart1.Init.OverSampling = UART_OVERSAMPLING_16;
  if (HAL_UART_Init(&huart1) != HAL_OK)
  {
    Error_Handler();
  }

}

static void MX_DMA_Init(void)
{

  /* DMA controller clock enable */
  __HAL_RCC_DMA2_CLK_ENABLE();

  /* DMA interrupt init */
  /* DMA2_Stream4_IRQn interrupt configuration */
  HAL_NVIC_SetPriority(DMA2_Stream4_IRQn, 2, 0);
  HAL_NVIC_EnableIRQ(DMA2_Stream4_IRQn);

}

static void MX_GPIO_Init(void)
{
  LL_GPIO_InitTypeDef GPIO_InitStruct = {0};

  /* GPIO Ports Clock Enable */
  LL_AHB1_GRP1_EnableClock(LL_AHB1_GRP1_PERIPH_GPIOC);
  LL_AHB1_GRP1_EnableClock(LL_AHB1_GRP1_PERIPH_GPIOH);
  LL_AHB1_GRP1_EnableClock(LL_AHB1_GRP1_PERIPH_GPIOA);
  LL_AHB1_GRP1_EnableClock(LL_AHB1_GRP1_PERIPH_GPIOB);

  /**/
  LL_GPIO_ResetOutputPin(MASTER_ENABLE_GPIO_Port, MASTER_ENABLE_Pin);

  /**/
  LL_GPIO_ResetOutputPin(GPIOA, GPIO_SHIFT_Pin|BOARD_ADDR0_Pin|BOARD_ADDR1_Pin|BOARD_ADDR2_Pin
                          |nCS_Pin);

  /**/
  LL_GPIO_ResetOutputPin(GPIOB, IN_LOAD_Pin|OUT_STORE_Pin|OUT_DATA_Pin);

  /**/
  GPIO_InitStruct.Pin = MASTER_ENABLE_Pin;
  GPIO_InitStruct.Mode = LL_GPIO_MODE_OUTPUT;
  GPIO_InitStruct.Speed = LL_GPIO_SPEED_FREQ_LOW;
  GPIO_InitStruct.OutputType = LL_GPIO_OUTPUT_PUSHPULL;
  GPIO_InitStruct.Pull = LL_GPIO_PULL_NO;
  LL_GPIO_Init(MASTER_ENABLE_GPIO_Port, &GPIO_InitStruct);

  /**/
  GPIO_InitStruct.Pin = BUTTON_Pin|nDRDY_Pin;
  GPIO_InitStruct.Mode = LL_GPIO_MODE_INPUT;
  GPIO_InitStruct.Pull = LL_GPIO_PULL_UP;
  LL_GPIO_Init(GPIOA, &GPIO_InitStruct);

  /**/
  GPIO_InitStruct.Pin = GPIO_SHIFT_Pin|BOARD_ADDR0_Pin|BOARD_ADDR1_Pin|BOARD_ADDR2_Pin
                          |nCS_Pin;
  GPIO_InitStruct.Mode = LL_GPIO_MODE_OUTPUT;
  GPIO_InitStruct.Speed = LL_GPIO_SPEED_FREQ_LOW;
  GPIO_InitStruct.OutputType = LL_GPIO_OUTPUT_PUSHPULL;
  GPIO_InitStruct.Pull = LL_GPIO_PULL_NO;
  LL_GPIO_Init(GPIOA, &GPIO_InitStruct);

  /**/
  GPIO_InitStruct.Pin = IN_DATA_Pin;
  GPIO_InitStruct.Mode = LL_GPIO_MODE_INPUT;
  GPIO_InitStruct.Pull = LL_GPIO_PULL_NO;
  LL_GPIO_Init(IN_DATA_GPIO_Port, &GPIO_InitStruct);

  /**/
  GPIO_InitStruct.Pin = IN_LOAD_Pin|OUT_STORE_Pin|OUT_DATA_Pin;
  GPIO_InitStruct.Mode = LL_GPIO_MODE_OUTPUT;
  GPIO_InitStruct.Speed = LL_GPIO_SPEED_FREQ_LOW;
  GPIO_InitStruct.OutputType = LL_GPIO_OUTPUT_PUSHPULL;
  GPIO_InitStruct.Pull = LL_GPIO_PULL_NO;
  LL_GPIO_Init(GPIOB, &GPIO_InitStruct);

}

void Error_Handler(void)
{
  /* USER CODE BEGIN Error_Handler_Debug */
  /* User can add his own implementation to report the HAL error return state */
  puts("HAL ERROR!!!");
  HAL_Delay(1000);
  __disable_irq();
  while (1)
  {
  }
  /* USER CODE END Error_Handler_Debug */
}
